# nrf9230_engb_application register map
Vendor: Nordic Semiconductor; Series: nRF92; File version: 1
CPU: CM33 r0p4, little endian, MPU, FPU, 3 interrupt priority bits, 480 interrupts, 4 SAU regions
Registers are 32-bit, read-write, reset 0x0 unless marked. A register's access mark holds for its fields unless they carry their own. Offsets are from the block's base; [hi:lo] are bit positions; lines under a group give offsets from that group; {n}, {i} and the like mark numbered series; 'fields as' and 'values as' point back to an identical list.

## GLOBAL_TWIM120_NS — I2C compatible Two-Wire Master Interface with EasyDMA 0
Base 0x4F8E8000
Same registers: GLOBAL_TWIM130_NS 0x4F9A5000 (alternate view of GLOBAL_SPIM130_NS), GLOBAL_TWIM131_NS 0x4F9A6000 (alternate view of GLOBAL_SPIM131_NS), GLOBAL_TWIM132_NS 0x4F9B5000 (alternate view of GLOBAL_SPIM132_NS), GLOBAL_TWIM133_NS 0x4F9B6000 (alternate view of GLOBAL_SPIM133_NS), GLOBAL_TWIM134_NS 0x4F9C5000 (alternate view of GLOBAL_SPIM134_NS), GLOBAL_TWIM135_NS 0x4F9C6000 (alternate view of GLOBAL_SPIM135_NS), GLOBAL_TWIM136_NS 0x4F9D5000 (alternate view of GLOBAL_SPIM136_NS), GLOBAL_TWIM137_NS 0x4F9D6000 (alternate view of GLOBAL_SPIM137_NS), GLOBAL_TWIM120_S 0x5F8E8000, GLOBAL_TWIM130_S 0x5F9A5000 (alternate view of GLOBAL_SPIM130_S), GLOBAL_TWIM131_S 0x5F9A6000 (alternate view of GLOBAL_SPIM131_S), GLOBAL_TWIM132_S 0x5F9B5000 (alternate view of GLOBAL_SPIM132_S), GLOBAL_TWIM133_S 0x5F9B6000 (alternate view of GLOBAL_SPIM133_S), GLOBAL_TWIM134_S 0x5F9C5000 (alternate view of GLOBAL_SPIM134_S), GLOBAL_TWIM135_S 0x5F9C6000 (alternate view of GLOBAL_SPIM135_S), GLOBAL_TWIM136_S 0x5F9D5000 (alternate view of GLOBAL_SPIM136_S), GLOBAL_TWIM137_S 0x5F9D6000 (alternate view of GLOBAL_SPIM137_S)
0x04 TASKS_STOP wo — Stop TWI transaction. Must be issued while the TWI master is not suspended.
  [0] TASKS_STOP
    1=Trigger task
0x0C TASKS_SUSPEND wo — Suspend TWI transaction
  [0] TASKS_SUSPEND
    1=Trigger task
0x10 TASKS_RESUME wo — Resume TWI transaction
  [0] TASKS_RESUME
    1=Trigger task
0x28 TASKS_DMA group — Peripheral tasks.
  0x00 RX group — Peripheral tasks.
    0x00 START wo — Starts operation using easyDMA to load the values. See peripheral description for operation using easyDMA.
      [0] START
        1=Trigger task
    0x04 STOP wo — Stops operation using easyDMA. This does not trigger an END event. After a STOP task, the easyDMA (channel) will also enter its lowest required power level.
      [0] STOP
        1=Trigger task
    {0x8+4k} ENABLEMATCH[{k}] (k=0..3) wo — Description collection: Enables the MATCH[n] event by setting the ENABLE[n] bit in the CONFIG register.
      [0] ENABLEMATCH — Enables the MATCH[n] event by setting the ENABLE[n] bit in the CONFIG register.
        1=Trigger task
    {0x18+4k} DISABLEMATCH[{k}] (k=0..3) wo — Description collection: Disables the MATCH[n] event by clearing the ENABLE[n] bit in the CONFIG register.
      [0] DISABLEMATCH — Disables the MATCH[n] event by clearing the ENABLE[n] bit in the CONFIG register.
        1=Trigger task
  0x28 TX group — Peripheral tasks.
    0x00 START wo — Starts operation using easyDMA to load the values. See peripheral description for operation using easyDMA.
      [0] START
        1=Trigger task
    0x04 STOP wo — Stops operation using easyDMA. This does not trigger an END event. After a STOP task, the easyDMA (channel) will also enter its lowest required power level.
      [0] STOP
        1=Trigger task
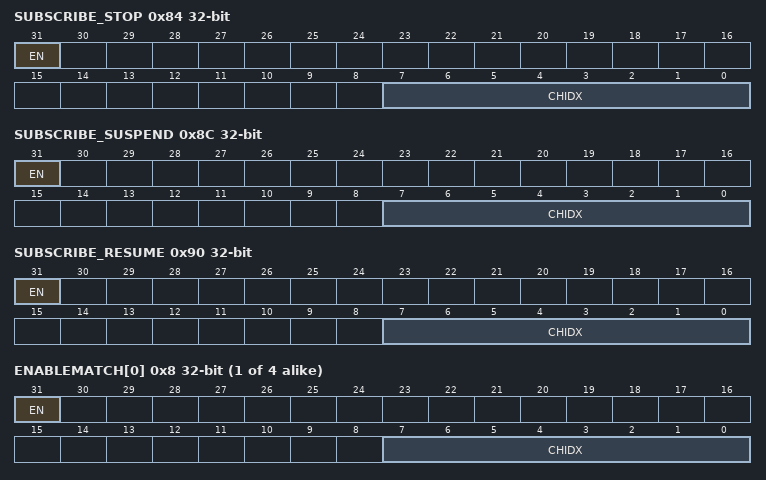
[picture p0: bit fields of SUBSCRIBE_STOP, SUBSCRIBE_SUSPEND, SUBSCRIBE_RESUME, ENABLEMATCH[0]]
0x84 SUBSCRIBE_STOP — Subscribe configuration for task STOP
  [31] EN
    0=Disabled (Disable subscription); 1=Enabled (Enable subscription)
  [7:0] CHIDX — DPPI channel that task STOP will subscribe to
0x8C SUBSCRIBE_SUSPEND — Subscribe configuration for task SUSPEND
  [31] EN
    values as SUBSCRIBE_STOP.EN
  [7:0] CHIDX — DPPI channel that task SUSPEND will subscribe to
0x90 SUBSCRIBE_RESUME — Subscribe configuration for task RESUME
  [31] EN
    values as SUBSCRIBE_STOP.EN
  [7:0] CHIDX — DPPI channel that task RESUME will subscribe to
0xA8 SUBSCRIBE_DMA group — Subscribe configuration for tasks
  0x00 RX group — Subscribe configuration for tasks
    0x00 START — Subscribe configuration for task START
      [31] EN
        values as SUBSCRIBE_STOP.EN
      [7:0] CHIDX — DPPI channel that task START will subscribe to
    0x04 STOP — Subscribe configuration for task STOP
      fields as SUBSCRIBE_STOP
    {0x8+4k} ENABLEMATCH[{k}] (k=0..3) — Description collection: Subscribe configuration for task ENABLEMATCH[n]
      [31] EN
        values as SUBSCRIBE_STOP.EN
      [7:0] CHIDX — DPPI channel that task ENABLEMATCH[n] will subscribe to
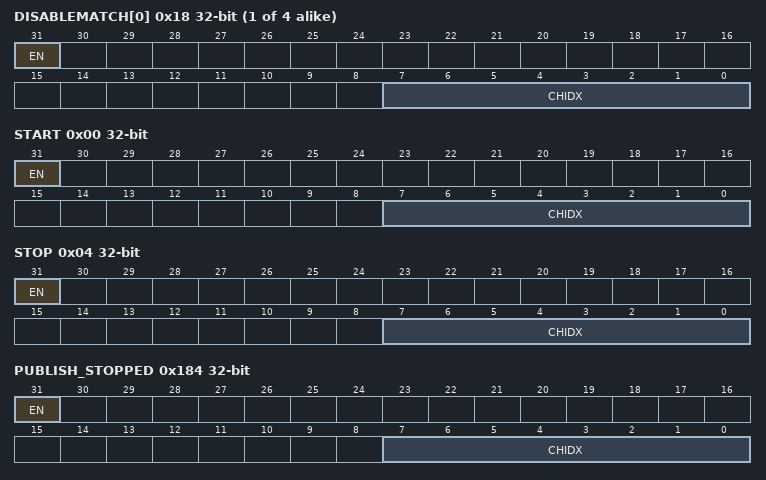
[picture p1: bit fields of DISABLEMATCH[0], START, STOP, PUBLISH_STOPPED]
    {0x18+4k} DISABLEMATCH[{k}] (k=0..3) — Description collection: Subscribe configuration for task DISABLEMATCH[n]
      [31] EN
        values as SUBSCRIBE_STOP.EN
      [7:0] CHIDX — DPPI channel that task DISABLEMATCH[n] will subscribe to
  0x28 TX group — Subscribe configuration for tasks
    0x00 START — Subscribe configuration for task START
      fields as SUBSCRIBE_DMA.RX.START
    0x04 STOP — Subscribe configuration for task STOP
      fields as SUBSCRIBE_STOP
0x104 EVENTS_STOPPED — TWI stopped
  [0] EVENTS_STOPPED
    0=NotGenerated (Event not generated); 1=Generated (Event generated)
0x114 EVENTS_ERROR — TWI error
  [0] EVENTS_ERROR
    values as EVENTS_STOPPED.EVENTS_STOPPED
0x120 EVENTS_BB — TWI byte boundary, generated before each byte that is sent or received
  [0] EVENTS_BB
    values as EVENTS_STOPPED.EVENTS_STOPPED
0x128 EVENTS_SUSPENDED — SUSPEND task has been issued, TWI traffic is now suspended.
  [0] EVENTS_SUSPENDED
    values as EVENTS_STOPPED.EVENTS_STOPPED
0x134 EVENTS_LASTRX — Byte boundary, starting to receive the last byte
  [0] EVENTS_LASTRX
    values as EVENTS_STOPPED.EVENTS_STOPPED
0x138 EVENTS_LASTTX — Byte boundary, starting to transmit the last byte
  [0] EVENTS_LASTTX
    values as EVENTS_STOPPED.EVENTS_STOPPED
0x14C EVENTS_DMA group — Peripheral events.
  0x00 RX group — Peripheral events.
    0x00 END — Generated after all MAXCNT bytes have been transferred Equivalent to eventDmaEnd[Channel]
      [0] END
        values as EVENTS_STOPPED.EVENTS_STOPPED
    0x04 READY — Generated when EasyDMA has buffered the .PTR and .MAXCNT registers for the channel, allowing them to be written to prepare for the next sequence.
      [0] READY
        values as EVENTS_STOPPED.EVENTS_STOPPED
    0x08 BUSERROR — An error occured during the bus transfer. This event is generated on an AHB / AXI error response.
      [0] BUSERROR
        values as EVENTS_STOPPED.EVENTS_STOPPED
    {0xC+4k} MATCH[{k}] (k=0..3) — Description collection: Pattern match is detected on the DMA data bus.
      [0] MATCH — Pattern match is detected on the DMA data bus.
        values as EVENTS_STOPPED.EVENTS_STOPPED
  0x1C TX group — Peripheral events.
    0x00 END — Generated after all MAXCNT bytes have been transferred Equivalent to eventDmaEnd[Channel]
      fields as EVENTS_DMA.RX.END
    0x04 READY — Generated when EasyDMA has buffered the .PTR and .MAXCNT registers for the channel, allowing them to be written to prepare for the next sequence.
      fields as EVENTS_DMA.RX.READY
    0x08 BUSERROR — An error occured during the bus transfer. This event is generated on an AHB / AXI error response.
      fields as EVENTS_DMA.RX.BUSERROR
0x184 PUBLISH_STOPPED — Publish configuration for event STOPPED
  [31] EN
    0=Disabled (Disable publishing); 1=Enabled (Enable publishing)
  [7:0] CHIDX — DPPI channel that event STOPPED will publish to
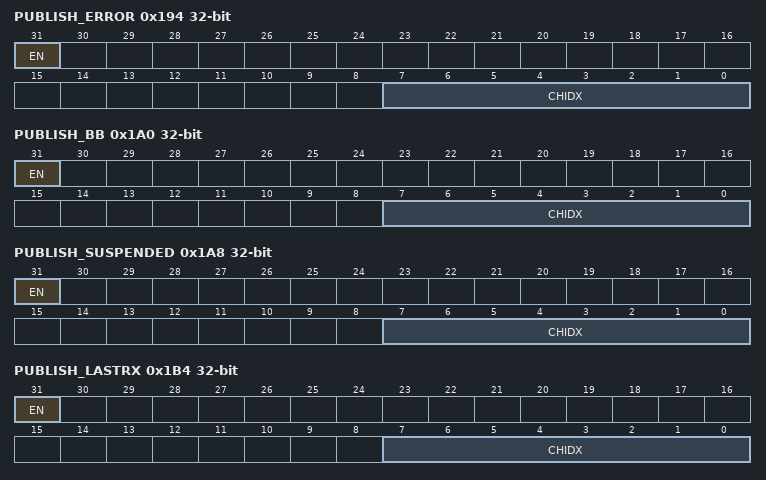
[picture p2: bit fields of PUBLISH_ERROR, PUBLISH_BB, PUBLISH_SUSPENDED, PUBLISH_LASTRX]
0x194 PUBLISH_ERROR — Publish configuration for event ERROR
  [31] EN
    values as PUBLISH_STOPPED.EN
  [7:0] CHIDX — DPPI channel that event ERROR will publish to
0x1A0 PUBLISH_BB — Publish configuration for event BB
  [31] EN
    values as PUBLISH_STOPPED.EN
  [7:0] CHIDX — DPPI channel that event BB will publish to
0x1A8 PUBLISH_SUSPENDED — Publish configuration for event SUSPENDED
  [31] EN
    values as PUBLISH_STOPPED.EN
  [7:0] CHIDX — DPPI channel that event SUSPENDED will publish to
0x1B4 PUBLISH_LASTRX — Publish configuration for event LASTRX
  [31] EN
    values as PUBLISH_STOPPED.EN
  [7:0] CHIDX — DPPI channel that event LASTRX will publish to
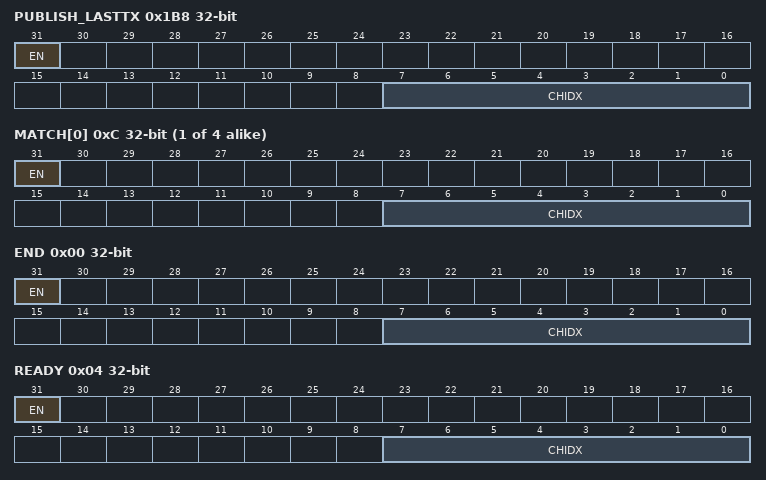
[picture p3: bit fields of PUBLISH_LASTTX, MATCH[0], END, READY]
0x1B8 PUBLISH_LASTTX — Publish configuration for event LASTTX
  [31] EN
    values as PUBLISH_STOPPED.EN
  [7:0] CHIDX — DPPI channel that event LASTTX will publish to
0x1CC PUBLISH_DMA group — Publish configuration for events
  0x00 RX group — Publish configuration for events
    0x00 END — Publish configuration for event END
      [31] EN
        values as PUBLISH_STOPPED.EN
      [7:0] CHIDX — DPPI channel that event END will publish to
    0x04 READY — Publish configuration for event READY
      [31] EN
        values as PUBLISH_STOPPED.EN
      [7:0] CHIDX — DPPI channel that event READY will publish to
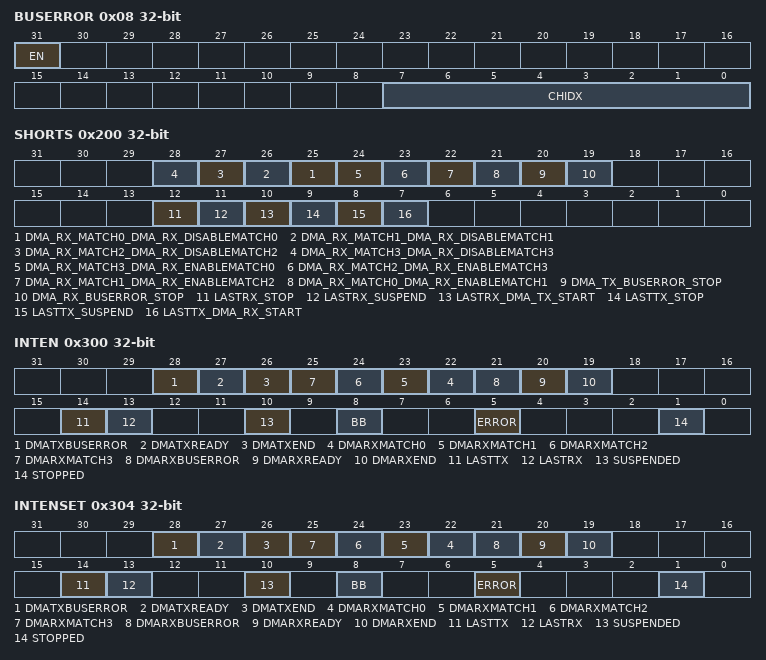
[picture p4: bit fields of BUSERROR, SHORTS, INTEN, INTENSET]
    0x08 BUSERROR — Publish configuration for event BUSERROR
      [31] EN
        values as PUBLISH_STOPPED.EN
      [7:0] CHIDX — DPPI channel that event BUSERROR will publish to
    {0xC+4k} MATCH[{k}] (k=0..3) — Description collection: Publish configuration for event MATCH[n]
      [31] EN
        values as PUBLISH_STOPPED.EN
      [7:0] CHIDX — DPPI channel that event MATCH[n] will publish to
  0x1C TX group — Publish configuration for events
    0x00 END — Publish configuration for event END
      fields as PUBLISH_DMA.RX.END
    0x04 READY — Publish configuration for event READY
      fields as PUBLISH_DMA.RX.READY
    0x08 BUSERROR — Publish configuration for event BUSERROR
      fields as PUBLISH_DMA.RX.BUSERROR
0x200 SHORTS — Shortcuts between local events and tasks
  [all] fields
    0=Disabled (Disable shortcut); 1=Enabled (Enable shortcut)
  [n+25] DMA_RX_MATCH{n}_DMA_RX_DISABLEMATCH{n} (n=0..3) — Shortcut between event DMA.RX.MATCH[n] and task DMA.RX.DISABLEMATCH[n]
  [24] DMA_RX_MATCH3_DMA_RX_ENABLEMATCH0 — Shortcut between event DMA.RX.MATCH[n] and task DMA.RX.ENABLEMATCH[0] Allows daisy-chaining match events.
  [23] DMA_RX_MATCH2_DMA_RX_ENABLEMATCH3 — Shortcut between event DMA.RX.MATCH[n] and task DMA.RX.ENABLEMATCH[3] Allows daisy-chaining match events.
  [22] DMA_RX_MATCH1_DMA_RX_ENABLEMATCH2 — Shortcut between event DMA.RX.MATCH[n] and task DMA.RX.ENABLEMATCH[2] Allows daisy-chaining match events.
  [21] DMA_RX_MATCH0_DMA_RX_ENABLEMATCH1 — Shortcut between event DMA.RX.MATCH[n] and task DMA.RX.ENABLEMATCH[1] Allows daisy-chaining match events.
  [20] DMA_TX_BUSERROR_STOP — Shortcut between event DMA.TX.BUSERROR and task STOP
  [19] DMA_RX_BUSERROR_STOP — Shortcut between event DMA.RX.BUSERROR and task STOP
  [12] LASTRX_STOP — Shortcut between event LASTRX and task STOP
  [11] LASTRX_SUSPEND — Shortcut between event LASTRX and task SUSPEND
  [10] LASTRX_DMA_TX_START — Shortcut between event LASTRX and task DMA.TX.START
  [9] LASTTX_STOP — Shortcut between event LASTTX and task STOP
  [8] LASTTX_SUSPEND — Shortcut between event LASTTX and task SUSPEND
  [7] LASTTX_DMA_RX_START — Shortcut between event LASTTX and task DMA.RX.START
0x300 INTEN — Enable or disable interrupt
  [all] fields
    0=Disabled; 1=Enabled
  [28] DMATXBUSERROR — Enable or disable interrupt for event DMATXBUSERROR
  [27] DMATXREADY — Enable or disable interrupt for event DMATXREADY
  [26] DMATXEND — Enable or disable interrupt for event DMATXEND
  [n+22] DMARXMATCH{n} (n=0..3) — Enable or disable interrupt for event DMARXMATCH[{n}]
  [21] DMARXBUSERROR — Enable or disable interrupt for event DMARXBUSERROR
  [20] DMARXREADY — Enable or disable interrupt for event DMARXREADY
  [19] DMARXEND — Enable or disable interrupt for event DMARXEND
  [14] LASTTX — Enable or disable interrupt for event LASTTX
  [13] LASTRX — Enable or disable interrupt for event LASTRX
  [10] SUSPENDED — Enable or disable interrupt for event SUSPENDED
  [8] BB — Enable or disable interrupt for event BB
  [5] ERROR — Enable or disable interrupt for event ERROR
  [1] STOPPED — Enable or disable interrupt for event STOPPED
0x304 INTENSET — Enable interrupt
  [all] fields
    on read: 0=Disabled (Read: Disabled); 1=Enabled (Read: Enabled) | on write: 1=Set (Enable)
  [28] DMATXBUSERROR — Write '1' to enable interrupt for event DMATXBUSERROR
  [27] DMATXREADY — Write '1' to enable interrupt for event DMATXREADY
  [26] DMATXEND — Write '1' to enable interrupt for event DMATXEND
  [n+22] DMARXMATCH{n} (n=0..3) — Write '1' to enable interrupt for event DMARXMATCH[{n}]
  [21] DMARXBUSERROR — Write '1' to enable interrupt for event DMARXBUSERROR
  [20] DMARXREADY — Write '1' to enable interrupt for event DMARXREADY
  [19] DMARXEND — Write '1' to enable interrupt for event DMARXEND
  [14] LASTTX — Write '1' to enable interrupt for event LASTTX
  [13] LASTRX — Write '1' to enable interrupt for event LASTRX
  [10] SUSPENDED — Write '1' to enable interrupt for event SUSPENDED
  [8] BB — Write '1' to enable interrupt for event BB
  [5] ERROR — Write '1' to enable interrupt for event ERROR
  [1] STOPPED — Write '1' to enable interrupt for event STOPPED
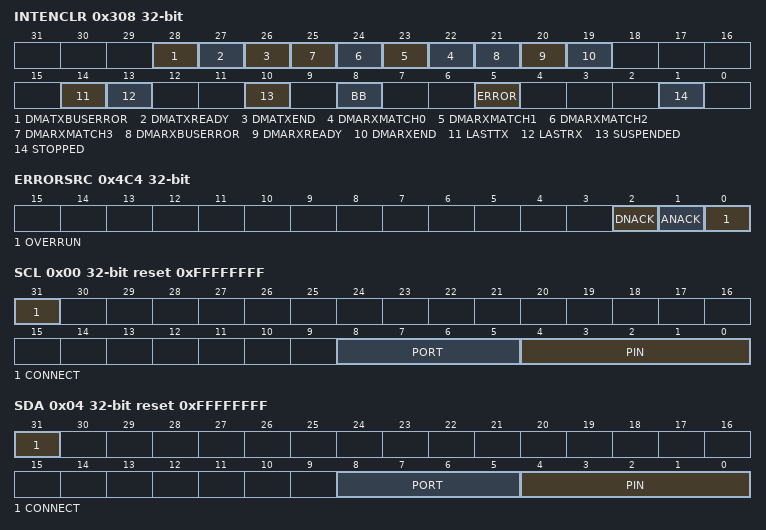
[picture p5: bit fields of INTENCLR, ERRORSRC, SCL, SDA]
0x308 INTENCLR — Disable interrupt
  [all] fields
    on read: 0=Disabled (Read: Disabled); 1=Enabled (Read: Enabled) | on write: 1=Clear (Disable)
  [28] DMATXBUSERROR — Write '1' to disable interrupt for event DMATXBUSERROR
  [27] DMATXREADY — Write '1' to disable interrupt for event DMATXREADY
  [26] DMATXEND — Write '1' to disable interrupt for event DMATXEND
  [n+22] DMARXMATCH{n} (n=0..3) — Write '1' to disable interrupt for event DMARXMATCH[{n}]
  [21] DMARXBUSERROR — Write '1' to disable interrupt for event DMARXBUSERROR
  [20] DMARXREADY — Write '1' to disable interrupt for event DMARXREADY
  [19] DMARXEND — Write '1' to disable interrupt for event DMARXEND
  [14] LASTTX — Write '1' to disable interrupt for event LASTTX
  [13] LASTRX — Write '1' to disable interrupt for event LASTRX
  [10] SUSPENDED — Write '1' to disable interrupt for event SUSPENDED
  [8] BB — Write '1' to disable interrupt for event BB
  [5] ERROR — Write '1' to disable interrupt for event ERROR
  [1] STOPPED — Write '1' to disable interrupt for event STOPPED
0x4C4 ERRORSRC write-1-clears — Error source
  [all] fields
    0=NotReceived (Error did not occur); 1=Received (Error occurred)
  [2] DNACK — NACK received after sending a data byte (write '1' to clear)
  [1] ANACK — NACK received after sending the address (write '1' to clear)
  [0] OVERRUN — Overrun error
0x500 ENABLE — Enable TWIM
  [3:0] ENABLE — Enable or disable TWIM
    0=Disabled (Disable TWIM); 6=Enabled (Enable TWIM)
0x504 CONFIG — Configuration register
  [2:1] RG ro — Internal read-only status information
    1=K100 (100 kbit/s); 3=K1000 (1000 kbps)
0x520 FMPLUS reset 0xE000000 — FREQUENCY threshold for switch from regular mode to to FastMode+
  [31:0] THRESHOLD — Threshold value
0x524 FREQUENCY reset 0x4000000 — TWI frequency. Accuracy depends on the HFCLK source selected.
  [31:0] FREQUENCY — TWI master clock frequency
    0x1980000=K100 (100 kbps); 0x4000000=K250 (250 kbps); 0x6400000=K400 (400 kbps); 0xFF00000=K1000 (1000 kbps)
0x588 ADDRESS — Address used in the TWI transfer
  [6:0] ADDRESS
0x600 PSEL group — Unspecified
  0x00 SCL reset 0xFFFFFFFF — Pin select for SCL signal
    [31] CONNECT — Connection
      1=Disconnected; 0=Connected
    [8:5] PORT — Port number
    [4:0] PIN — Pin number
  0x04 SDA reset 0xFFFFFFFF — Pin select for SDA signal
    fields as PSEL.SCL
0x700 DMA group — Unspecified
  0x00 RX group — Unspecified
    0x00 ENABLE — Register doesn't do anything. Can be written and read, but has no functionality attached.
      [0] ENABLE
        0=Disabled; 1=Enabled
    0x04 PTR — RAM buffer start address
      [31:0] PTR — RAM buffer start address for this EasyDMA channel. This address is a word aligned Data RAM address.
    0x08 MAXCNT — Maximum number of bytes in channel buffer
      [14:0] MAXCNT
    0x0C AMOUNT ro — Number of bytes transferred in the last transaction, updated after the END event. Also updated after each MATCH event.
      [14:0] AMOUNT — Number of bytes transferred in the last transaction. In case of NACK error, includes the NACK'ed byte.
    0x10 CURRENTAMOUNT ro — Number of bytes transferred in the current transaction
      [14:0] AMOUNT — Number of bytes transferred in the current transaction. Continuously updated. Updated when data leaves the internal FIFO and is transferred to the destination.
    0x14 LIST — EasyDMA list type
      [2:0] TYPE — List type
        0=Disabled (Disable EasyDMA list); 1=ArrayList (Use array list)
    0x1C TERMINATEONBUSERROR — Terminate the transaction if a BUSERROR event is detected.
      [0] ENABLE
        0=Disabled; 1=Enabled
    0x20 BUSERRORADDRESS ro — Address of transaction that generated the last BUSERROR event.
      [31:0] ADDRESS
    0x24 MATCH group — Registers to control the behavior of the pattern matcher engine
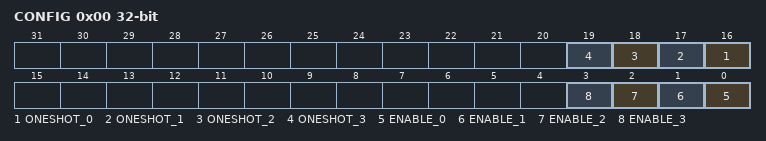
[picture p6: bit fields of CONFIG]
      0x00 CONFIG — Configure individual match events
        [n+16] ONESHOT_{n} (n=0..3) — Configure match filter {n} as one-shot or sticky
          0=Continuous (Match filter stays enabled until disabled by task); 1=Oneshot (Match filter stays enabled until next data word is received)
        [n] ENABLE_{n} (n=0..3) — Enable match filter {n}
          0=Disabled (Match filter disabled); 1=Enabled (Match filter enabled)
      {0x4+4l} CANDIDATE[{l}] (l=0..3) — Description collection: The data to look for - any match will trigger the MATCH[n] event, if enabled.
        [31:0] DATA — Data to look for
  0x38 TX group — Unspecified
    0x00 ENABLE — Register doesn't do anything. Can be written and read, but has no functionality attached.
      [0] ENABLE
        0=Disabled; 1=Enabled
    0x04 PTR — RAM buffer start address
      fields as DMA.RX.PTR
    0x08 MAXCNT — Maximum number of bytes in channel buffer
      [14:0] MAXCNT
    0x0C AMOUNT ro — Number of bytes transferred in the last transaction, updated after the END event. Also updated after each MATCH event.
      fields as DMA.RX.AMOUNT
    0x10 CURRENTAMOUNT ro — Number of bytes transferred in the current transaction
      fields as DMA.RX.CURRENTAMOUNT
    0x14 LIST — EasyDMA list type
      fields as DMA.RX.LIST
    0x1C TERMINATEONBUSERROR — Terminate the transaction if a BUSERROR event is detected.
      [0] ENABLE
        0=Disabled; 1=Enabled
    0x20 BUSERRORADDRESS ro — Address of transaction that generated the last BUSERROR event.
      [31:0] ADDRESS
